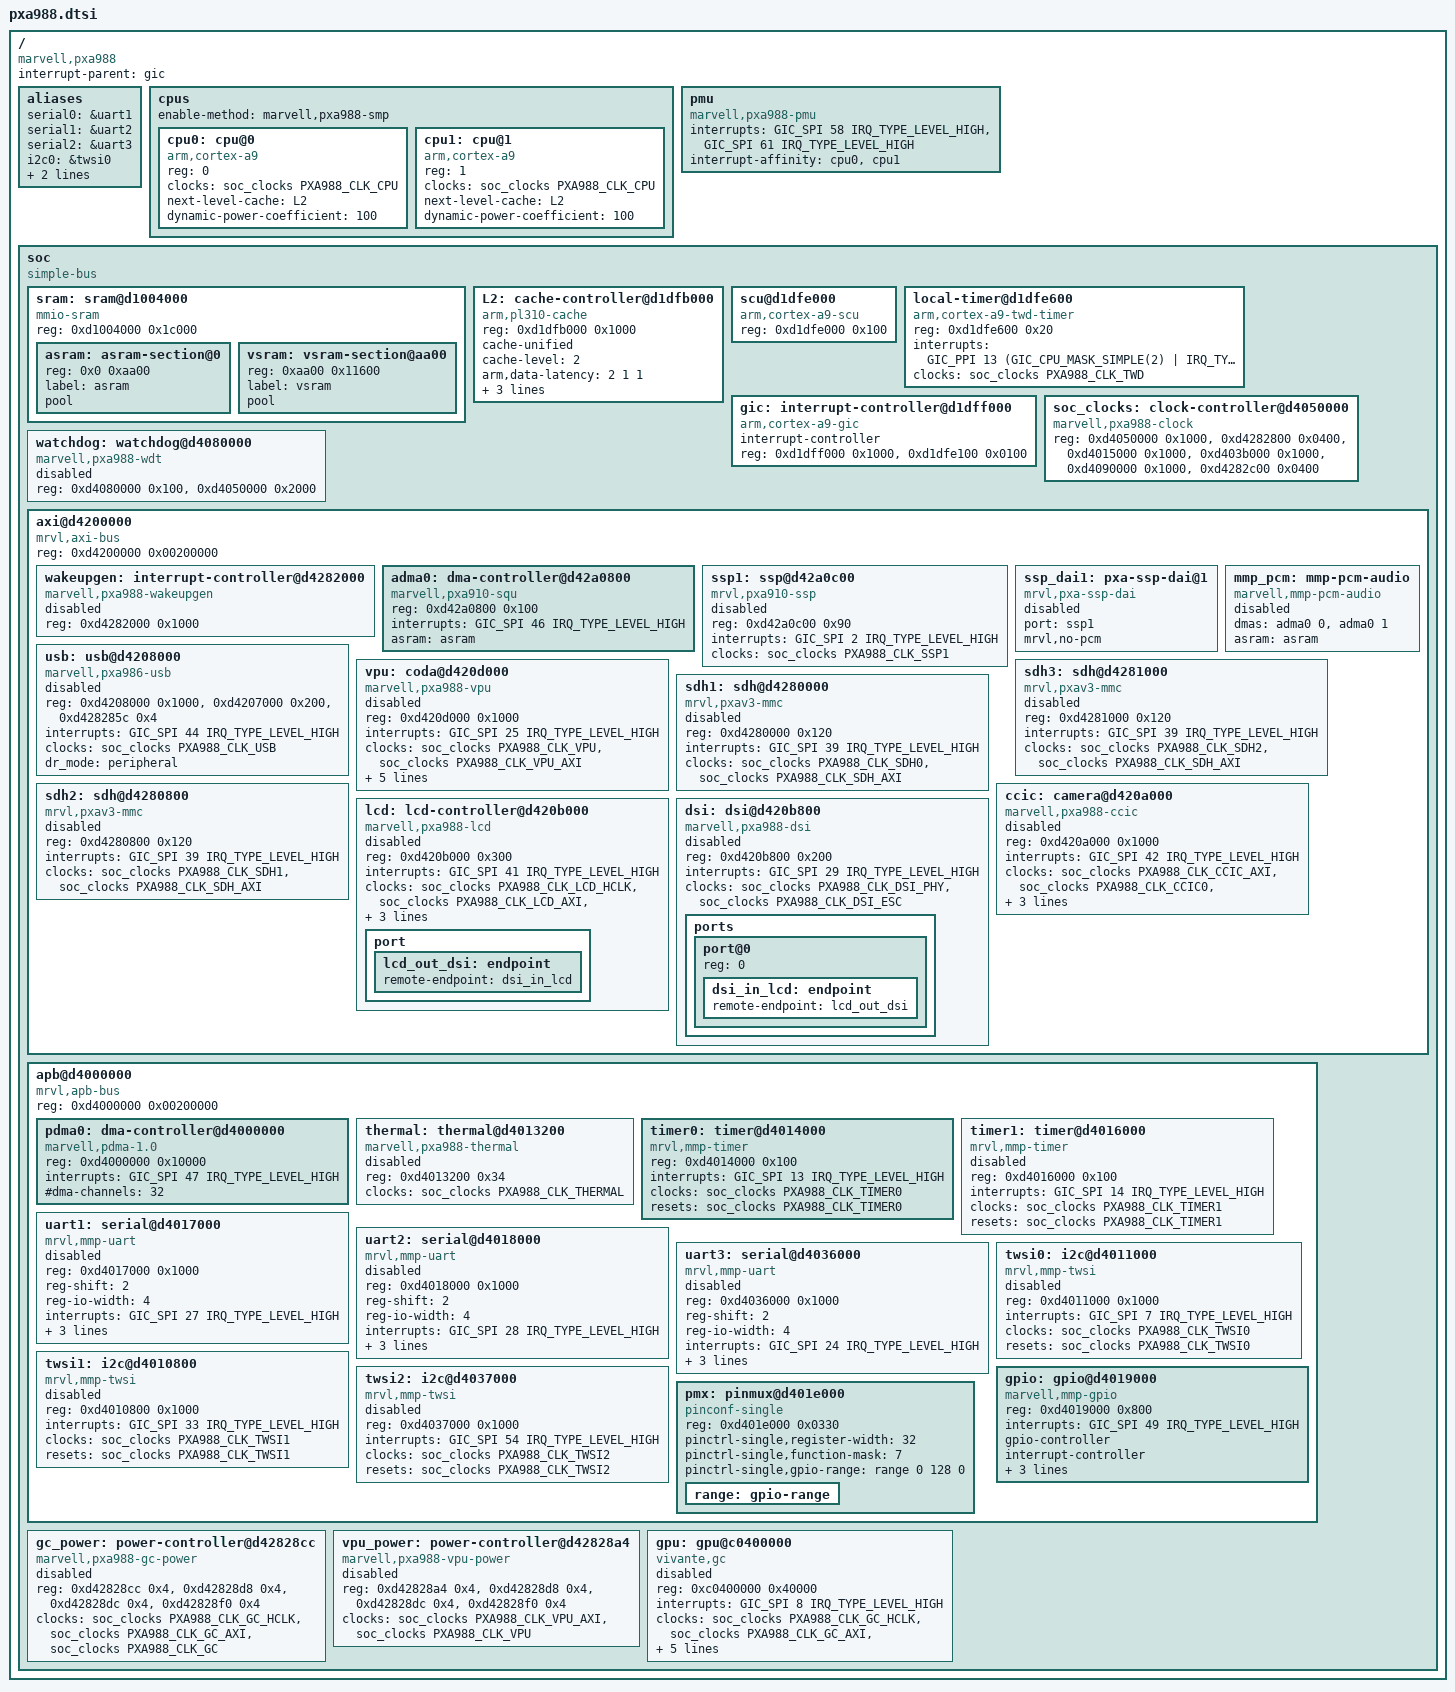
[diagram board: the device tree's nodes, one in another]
// SPDX-License-Identifier: GPL-2.0
/*
 * Marvell PXA988 / PXA986 (dual Cortex-A9) SoC Device Tree
 *
 * Copyright (C) 2012-2013 Marvell International Ltd.
 */

#include <dt-bindings/interrupt-controller/arm-gic.h>
#include <dt-bindings/interrupt-controller/irq.h>
#include <dt-bindings/clock/marvell,pxa988.h>
#include <dt-bindings/pinctrl/marvell,pxa988-pinfunc.h>

/ {
	compatible = "marvell,pxa988";
	#address-cells = <1>;
	#size-cells = <1>;
	interrupt-parent = <&gic>;

	aliases {
		serial0 = &uart1;
		serial1 = &uart2;
		serial2 = &uart3;
		i2c0 = &twsi0;
		i2c1 = &twsi1;
		i2c2 = &twsi2;
	};

	cpus {
		#address-cells = <1>;
		#size-cells = <0>;
		enable-method = "marvell,pxa988-smp";

		cpu0: cpu@0 {
			device_type = "cpu";
			compatible = "arm,cortex-a9";
			reg = <0>;
			clocks = <&soc_clocks PXA988_CLK_CPU>;
			clock-names = "cpu";
			next-level-cache = <&L2>;
			dynamic-power-coefficient = <100>;
			#cooling-cells = <2>;
		};

		cpu1: cpu@1 {
			device_type = "cpu";
			compatible = "arm,cortex-a9";
			reg = <1>;
			clocks = <&soc_clocks PXA988_CLK_CPU>;
			clock-names = "cpu";
			next-level-cache = <&L2>;
			dynamic-power-coefficient = <100>;
			#cooling-cells = <2>;
		};
	};

	pmu: pmu {
		compatible = "marvell,pxa988-pmu", "arm,cortex-a9-pmu";
		interrupts = <GIC_SPI 58 IRQ_TYPE_LEVEL_HIGH>,
			     <GIC_SPI 61 IRQ_TYPE_LEVEL_HIGH>;
		interrupt-affinity = <&cpu0>, <&cpu1>;
	};

	soc {
		compatible = "simple-bus";
		#address-cells = <1>;
		#size-cells = <1>;
		ranges;

		sram: sram@d1004000 {
			compatible = "mmio-sram";
			reg = <0xd1004000 0x1c000>;
			#address-cells = <1>;
			#size-cells = <1>;
			ranges = <0 0xd1004000 0x1c000>;

			asram: asram-section@0 {
				reg = <0x0 0xaa00>;
				label = "asram";
				pool;
			};

			vsram: vsram-section@aa00 {
				reg = <0xaa00 0x11600>;
				label = "vsram";
				pool;
			};
		};

		L2: cache-controller@d1dfb000 {
			compatible = "arm,pl310-cache";
			reg = <0xd1dfb000 0x1000>;
			cache-unified;
			cache-level = <2>;
			arm,data-latency = <2 1 1>;
			arm,tag-latency = <2 1 1>;
			arm,standby-mode = <1>;
			arm,dynamic-clock-gating = <1>;
		};

		scu@d1dfe000 {
			compatible = "arm,cortex-a9-scu";
			reg = <0xd1dfe000 0x100>;
		};

		local-timer@d1dfe600 {
			compatible = "arm,cortex-a9-twd-timer";
			reg = <0xd1dfe600 0x20>;
			interrupts = <GIC_PPI 13 (GIC_CPU_MASK_SIMPLE(2) | IRQ_TYPE_EDGE_RISING)>;
			clocks = <&soc_clocks PXA988_CLK_TWD>;
		};

		gic: interrupt-controller@d1dff000 {
			compatible = "arm,cortex-a9-gic";
			#interrupt-cells = <3>;
			#address-cells = <0>;
			interrupt-controller;
			reg = <0xd1dff000 0x1000>,
			      <0xd1dfe100 0x0100>;
		};

		soc_clocks: clock-controller@d4050000 {
			compatible = "marvell,pxa988-clock";
			reg = <0xd4050000 0x1000>,
			      <0xd4282800 0x0400>,
			      <0xd4015000 0x1000>,
			      <0xd403b000 0x1000>,
			      <0xd4090000 0x1000>,
			      <0xd4282c00 0x0400>;
			reg-names = "mpmu", "apmu", "apbc", "apbcp", "apbs", "ciu";
			#clock-cells = <1>;
			#reset-cells = <1>;
		};

		watchdog: watchdog@d4080000 {
			compatible = "marvell,pxa988-wdt";
			reg = <0xd4080000 0x100>,
			      <0xd4050000 0x2000>;
			reg-names = "wdt", "mpmu";
			status = "disabled";
		};

		axi@d4200000 {
			compatible = "mrvl,axi-bus", "simple-bus";
			#address-cells = <1>;
			#size-cells = <1>;
			reg = <0xd4200000 0x00200000>;
			ranges;

			/* ICU / WakeupGen stub for Phase 05 SMP & PM */
			wakeupgen: interrupt-controller@d4282000 {
				compatible = "marvell,pxa988-wakeupgen";
				reg = <0xd4282000 0x1000>;
				status = "disabled";
			};

			adma0: dma-controller@d42a0800 {
				compatible = "marvell,pxa910-squ";
				reg = <0xd42a0800 0x100>;
				interrupts = <GIC_SPI 46 IRQ_TYPE_LEVEL_HIGH>;
				#dma-cells = <1>;
				asram = <&asram>;
			};

			ssp1: ssp@d42a0c00 {
				compatible = "mrvl,pxa910-ssp";
				reg = <0xd42a0c00 0x90>;
				interrupts = <GIC_SPI 2 IRQ_TYPE_LEVEL_HIGH>;
				clocks = <&soc_clocks PXA988_CLK_SSP1>;
				status = "disabled";
			};

			ssp_dai1: pxa-ssp-dai@1 {
				compatible = "mrvl,pxa-ssp-dai";
				port = <&ssp1>;
				mrvl,no-pcm;
				status = "disabled";
			};

			mmp_pcm: mmp-pcm-audio {
				compatible = "marvell,mmp-pcm-audio";
				dmas = <&adma0 0>, <&adma0 1>;
				dma-names = "tx", "rx";
				asram = <&asram>;
				status = "disabled";
			};

			usb: usb@d4208000 {
				compatible = "marvell,pxa986-usb", "marvell,pxa988-usb";
				reg = <0xd4208000 0x1000>,
				      <0xd4207000 0x200>,
				      <0xd428285c 0x4>;
				reg-names = "controller", "phy", "clock";
				interrupts = <GIC_SPI 44 IRQ_TYPE_LEVEL_HIGH>;
				clocks = <&soc_clocks PXA988_CLK_USB>;
				clock-names = "usb";
				dr_mode = "peripheral";
				status = "disabled";
			};

			vpu: coda@d420d000 {
				compatible = "marvell,pxa988-vpu";
				reg = <0xd420d000 0x1000>;
				interrupts = <GIC_SPI 25 IRQ_TYPE_LEVEL_HIGH>;
				clocks = <&soc_clocks PXA988_CLK_VPU>,
					 <&soc_clocks PXA988_CLK_VPU_AXI>;
				clock-names = "per", "ahb";
				assigned-clocks = <&soc_clocks PXA988_CLK_VPU>,
						  <&soc_clocks PXA988_CLK_VPU_AXI>;
				assigned-clock-rates = <156000000>, <156000000>;
				iram = <&vsram>;
				power-domains = <&vpu_power>;
				status = "disabled";
			};

			sdh3: sdh@d4281000 {
				compatible = "mrvl,pxav3-mmc";
				reg = <0xd4281000 0x120>;
				interrupts = <GIC_SPI 39 IRQ_TYPE_LEVEL_HIGH>;
				clocks = <&soc_clocks PXA988_CLK_SDH2>,
					 <&soc_clocks PXA988_CLK_SDH_AXI>;
				clock-names = "io", "core";
				status = "disabled";
			};

			sdh1: sdh@d4280000 {
				compatible = "mrvl,pxav3-mmc";
				reg = <0xd4280000 0x120>;
				interrupts = <GIC_SPI 39 IRQ_TYPE_LEVEL_HIGH>;
				clocks = <&soc_clocks PXA988_CLK_SDH0>,
					 <&soc_clocks PXA988_CLK_SDH_AXI>;
				clock-names = "io", "core";
				status = "disabled";
			};

			sdh2: sdh@d4280800 {
				compatible = "mrvl,pxav3-mmc";
				reg = <0xd4280800 0x120>;
				interrupts = <GIC_SPI 39 IRQ_TYPE_LEVEL_HIGH>;
				clocks = <&soc_clocks PXA988_CLK_SDH1>,
					 <&soc_clocks PXA988_CLK_SDH_AXI>;
				clock-names = "io", "core";
				status = "disabled";
			};

			ccic: camera@d420a000 {
				compatible = "marvell,pxa988-ccic", "marvell,mmp2-ccic";
				reg = <0xd420a000 0x1000>;
				interrupts = <GIC_SPI 42 IRQ_TYPE_LEVEL_HIGH>;
				clocks = <&soc_clocks PXA988_CLK_CCIC_AXI>,
					 <&soc_clocks PXA988_CLK_CCIC0>,
					 <&soc_clocks PXA988_CLK_CCIC0_PHY>,
					 <&soc_clocks PXA988_CLK_LCD_HCLK>;
				clock-names = "axi", "func", "phy", "hclk";
				#clock-cells = <0>;
				clock-output-names = "cam-mclk";
				status = "disabled";
			};

			lcd: lcd-controller@d420b000 {
				compatible = "marvell,pxa988-lcd";
				reg = <0xd420b000 0x300>;
				interrupts = <GIC_SPI 41 IRQ_TYPE_LEVEL_HIGH>;
				clocks = <&soc_clocks PXA988_CLK_LCD_HCLK>,
					 <&soc_clocks PXA988_CLK_LCD_AXI>,
					 <&soc_clocks PXA988_CLK_LCD>,
					 <&soc_clocks PXA988_CLK_DSI_PHY>,
					 <&soc_clocks PXA988_CLK_DSI_ESC>;
				clock-names = "hclk", "axi", "lcd",
					      "dsi_phy", "dsi_esc";
				status = "disabled";

				port {
					lcd_out_dsi: endpoint {
						remote-endpoint = <&dsi_in_lcd>;
					};
				};
			};

			dsi: dsi@d420b800 {
				compatible = "marvell,pxa988-dsi";
				reg = <0xd420b800 0x200>;
				interrupts = <GIC_SPI 29 IRQ_TYPE_LEVEL_HIGH>;
				clocks = <&soc_clocks PXA988_CLK_DSI_PHY>,
					 <&soc_clocks PXA988_CLK_DSI_ESC>;
				clock-names = "dsi_phy", "dsi_esc";
				status = "disabled";

				ports {
					#address-cells = <1>;
					#size-cells = <0>;

					port@0 {
						reg = <0>;
						dsi_in_lcd: endpoint {
							remote-endpoint = <&lcd_out_dsi>;
						};
					};
				};
			};
		};

		apb@d4000000 {
			compatible = "mrvl,apb-bus", "simple-bus";
			#address-cells = <1>;
			#size-cells = <1>;
			reg = <0xd4000000 0x00200000>;
			ranges;

			pdma0: dma-controller@d4000000 {
				compatible = "marvell,pdma-1.0";
				reg = <0xd4000000 0x10000>;
				interrupts = <GIC_SPI 47 IRQ_TYPE_LEVEL_HIGH>;
				#dma-cells = <1>;
				#dma-channels = <32>;
			};

			thermal: thermal@d4013200 {
				compatible = "marvell,pxa988-thermal";
				reg = <0xd4013200 0x34>;
				clocks = <&soc_clocks PXA988_CLK_THERMAL>;
				#thermal-sensor-cells = <0>;
				status = "disabled";
			};

			timer0: timer@d4014000 {
				compatible = "mrvl,mmp-timer";
				reg = <0xd4014000 0x100>;
				interrupts = <GIC_SPI 13 IRQ_TYPE_LEVEL_HIGH>;
				clocks = <&soc_clocks PXA988_CLK_TIMER0>;
				resets = <&soc_clocks PXA988_CLK_TIMER0>;
			};

			timer1: timer@d4016000 {
				compatible = "mrvl,mmp-timer";
				reg = <0xd4016000 0x100>;
				interrupts = <GIC_SPI 14 IRQ_TYPE_LEVEL_HIGH>;
				clocks = <&soc_clocks PXA988_CLK_TIMER1>;
				resets = <&soc_clocks PXA988_CLK_TIMER1>;
				status = "disabled";
			};

			uart1: serial@d4017000 {
				compatible = "mrvl,mmp-uart";
				reg = <0xd4017000 0x1000>;
				reg-shift = <2>;
				reg-io-width = <4>;
				interrupts = <GIC_SPI 27 IRQ_TYPE_LEVEL_HIGH>;
				clocks = <&soc_clocks PXA988_CLK_UART0>;
				resets = <&soc_clocks PXA988_CLK_UART0>;
				dmas = <&pdma0 21
					&pdma0 22>;
				dma-names = "rx", "tx";
				status = "disabled";
			};

			uart2: serial@d4018000 {
				compatible = "mrvl,mmp-uart";
				reg = <0xd4018000 0x1000>;
				reg-shift = <2>;
				reg-io-width = <4>;
				interrupts = <GIC_SPI 28 IRQ_TYPE_LEVEL_HIGH>;
				clocks = <&soc_clocks PXA988_CLK_UART1>;
				resets = <&soc_clocks PXA988_CLK_UART1>;
				dmas = <&pdma0 23
					&pdma0 24>;
				dma-names = "rx", "tx";
				status = "disabled";
			};

			uart3: serial@d4036000 {
				compatible = "mrvl,mmp-uart";
				reg = <0xd4036000 0x1000>;
				reg-shift = <2>;
				reg-io-width = <4>;
				interrupts = <GIC_SPI 24 IRQ_TYPE_LEVEL_HIGH>;
				clocks = <&soc_clocks PXA988_CLK_UART2>;
				resets = <&soc_clocks PXA988_CLK_UART2>;
				dmas = <&pdma0 4
					&pdma0 5>;
				dma-names = "rx", "tx";
				status = "disabled";
			};

			twsi0: i2c@d4011000 {
				compatible = "mrvl,mmp-twsi";
				reg = <0xd4011000 0x1000>;
				interrupts = <GIC_SPI 7 IRQ_TYPE_LEVEL_HIGH>;
				clocks = <&soc_clocks PXA988_CLK_TWSI0>;
				resets = <&soc_clocks PXA988_CLK_TWSI0>;
				#address-cells = <1>;
				#size-cells = <0>;
				status = "disabled";
			};

			twsi1: i2c@d4010800 {
				compatible = "mrvl,mmp-twsi";
				reg = <0xd4010800 0x1000>;
				interrupts = <GIC_SPI 33 IRQ_TYPE_LEVEL_HIGH>;
				clocks = <&soc_clocks PXA988_CLK_TWSI1>;
				resets = <&soc_clocks PXA988_CLK_TWSI1>;
				#address-cells = <1>;
				#size-cells = <0>;
				status = "disabled";
			};

			twsi2: i2c@d4037000 {
				compatible = "mrvl,mmp-twsi";
				reg = <0xd4037000 0x1000>;
				interrupts = <GIC_SPI 54 IRQ_TYPE_LEVEL_HIGH>;
				clocks = <&soc_clocks PXA988_CLK_TWSI2>;
				resets = <&soc_clocks PXA988_CLK_TWSI2>;
				#address-cells = <1>;
				#size-cells = <0>;
				status = "disabled";
			};

			gpio: gpio@d4019000 {
				compatible = "marvell,mmp-gpio";
				reg = <0xd4019000 0x800>;
				interrupts = <GIC_SPI 49 IRQ_TYPE_LEVEL_HIGH>;
				interrupt-names = "gpio_mux";
				gpio-controller;
				#gpio-cells = <2>;
				interrupt-controller;
				#interrupt-cells = <2>;
				clocks = <&soc_clocks PXA988_CLK_GPIO>;
				resets = <&soc_clocks PXA988_CLK_GPIO>;
				gpio-ranges = <&pmx 0 0 128>;
			};

			pmx: pinmux@d401e000 {
				compatible = "pinconf-single";
				reg = <0xd401e000 0x0330>;
				#address-cells = <1>;
				#size-cells = <0>;
				#pinctrl-cells = <1>;
				#gpio-range-cells = <3>;

				pinctrl-single,register-width = <32>;
				pinctrl-single,function-mask = <7>;

				pinctrl-single,gpio-range = <
					&range 0 128 0
				>;

				range: gpio-range {
					#pinctrl-single,gpio-range-cells = <3>;
				};
			};
		};

		gc_power: power-controller@d42828cc {
			compatible = "marvell,pxa988-gc-power";
			reg = <0xd42828cc 0x4>,
			      <0xd42828d8 0x4>,
			      <0xd42828dc 0x4>,
			      <0xd42828f0 0x4>;
			reg-names = "apmu-gc", "pwr-ctrl", "pwr-tmr", "pwr-stat";
			clocks = <&soc_clocks PXA988_CLK_GC_HCLK>,
				 <&soc_clocks PXA988_CLK_GC_AXI>,
				 <&soc_clocks PXA988_CLK_GC>;
			clock-names = "reg", "bus", "core";
			#power-domain-cells = <0>;
			status = "disabled";
		};

		vpu_power: power-controller@d42828a4 {
			compatible = "marvell,pxa988-vpu-power";
			reg = <0xd42828a4 0x4>,
			      <0xd42828d8 0x4>,
			      <0xd42828dc 0x4>,
			      <0xd42828f0 0x4>;
			reg-names = "apmu-vpu", "pwr-ctrl", "pwr-tmr", "pwr-stat";
			clocks = <&soc_clocks PXA988_CLK_VPU_AXI>,
				 <&soc_clocks PXA988_CLK_VPU>;
			clock-names = "bus", "core";
			#power-domain-cells = <0>;
			status = "disabled";
		};

		gpu: gpu@c0400000 {
			compatible = "vivante,gc";
			reg = <0xc0400000 0x40000>;
			interrupts = <GIC_SPI 8 IRQ_TYPE_LEVEL_HIGH>;
			clocks = <&soc_clocks PXA988_CLK_GC_HCLK>,
				 <&soc_clocks PXA988_CLK_GC_AXI>,
				 <&soc_clocks PXA988_CLK_GC>;
			clock-names = "reg", "bus", "core";
			assigned-clocks = <&soc_clocks PXA988_CLK_GC>,
					  <&soc_clocks PXA988_CLK_GC_AXI>;
			assigned-clock-rates = <156000000>, <208000000>;
			power-domains = <&gc_power>;
			status = "disabled";
		};
	};
};
